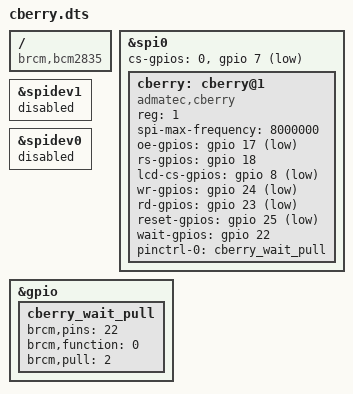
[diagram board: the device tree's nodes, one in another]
// SPDX-License-Identifier: GPL-2.0
/*
 * Device tree overlay for the admatec C-Berry 320x240 LCD module.
 *
 * Build:
 *   dtc -@ -I dts -O dtb -o cberry.dtbo cberry.dts
 *
 * Install:
 *   sudo cp cberry.dtbo /boot/firmware/overlays/
 *   echo "dtoverlay=cberry" | sudo tee -a /boot/firmware/config.txt
 *
 * Wiring (BCM numbering, matches the original C-Berry HAT):
 *   GPIO 7  - SPI0 CE1 (data strobe to the on-board shift register)
 *   GPIO 8  - RAIO chip select
 *   GPIO 9  - SPI0 MISO
 *   GPIO 10 - SPI0 MOSI
 *   GPIO 11 - SPI0 SCLK
 *   GPIO 17 - OE  (output enable, level shifter)
 *   GPIO 18 - RS  (register / data select)
 *   GPIO 22 - WAIT (busy in)
 *   GPIO 23 - RD  (read strobe)
 *   GPIO 24 - WR  (write strobe)
 *   GPIO 25 - RST (hard reset)
 *   GPIO 27 - INT (interrupt in, currently unused)
 */

/dts-v1/;
/plugin/;

/ {
	compatible = "brcm,bcm2835";

	fragment@0 {
		target = <&spi0>;
		__overlay__ {
			status = "okay";
			/*
			 * The Pi base DT pins both SPI0 chip-selects to GPIOs:
			 *   cs-gpios = <&gpio 8 1>, <&gpio 7 1>;
			 * That permanently reserves GPIO 8, which is also the
			 * RAIO chip-select on the C-Berry HAT. Override the list:
			 * slot 0 -> native HW CS (placeholder 0), slot 1 -> our
			 * SPI device on CE1 (GPIO 7).
			 */
			cs-gpios = <0>, <&gpio 7 1>;
		};
	};

	/* Disable the default spidev1.0 so we can claim CE1. */
	fragment@1 {
		target = <&spidev1>;
		__overlay__ {
			status = "disabled";
		};
	};

	/*
	 * Disable spidev0.0 too: with cs-gpios slot 0 set to <0> the
	 * SPI core would still spawn spidev0 on native HW CE0 (GPIO 8),
	 * stealing the line we need for RAIO_CS.
	 */
	fragment@4 {
		target = <&spidev0>;
		__overlay__ {
			status = "disabled";
		};
	};

	/*
	 * The vendor reference code enables the internal pull-up on the
	 * WAIT line; without it the pin floats and the RAIO busy-wait can
	 * either time out or, worse, return "ready" before the controller
	 * actually is.
	 */
	fragment@5 {
		target = <&gpio>;
		__overlay__ {
			cberry_wait_pull: cberry_wait_pull {
				brcm,pins = <22>;
				brcm,function = <0>; /* input */
				brcm,pull = <2>;     /* pull-up */
			};
		};
	};

	fragment@2 {
		target = <&spi0>;
		__overlay__ {
			#address-cells = <1>;
			#size-cells = <0>;

			cberry: cberry@1 {
				compatible = "admatec,cberry";
				reg = <1>;	/* SPI0 CE1 */
				spi-max-frequency = <8000000>;
				/* SPI mode 0: neither spi-cpol nor spi-cpha set */
				status = "okay";

				/* All output strobes are active low on the C-Berry HAT. */
				oe-gpios     = <&gpio 17 1>;
				rs-gpios     = <&gpio 18 0>;	/* RS: 1=register, 0=data */
				lcd-cs-gpios = <&gpio  8 1>;	/* RAIO_CS (NOT the SPI CE) */
				wr-gpios     = <&gpio 24 1>;	/* WR strobe */
				rd-gpios     = <&gpio 23 1>;	/* RD strobe (kept deasserted) */
				reset-gpios = <&gpio 25 1>;	/* hard reset */
				wait-gpios  = <&gpio 22 0>;	/* input: 1 = ready */

				pinctrl-names = "default";
				pinctrl-0 = <&cberry_wait_pull>;
			};
		};
	};
};
